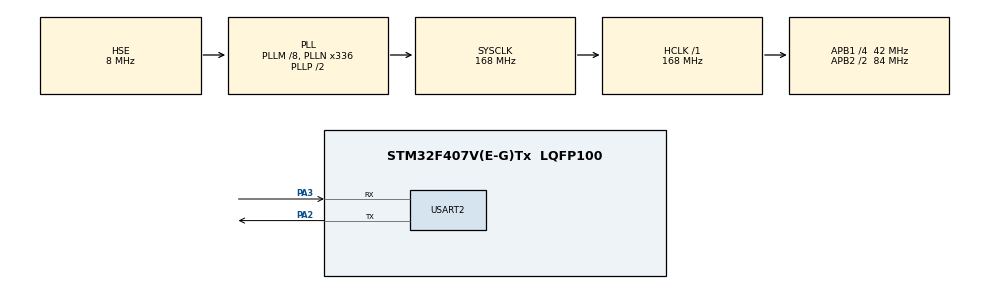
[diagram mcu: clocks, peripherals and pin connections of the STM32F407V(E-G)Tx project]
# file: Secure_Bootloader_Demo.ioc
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MBEDTLS.MBEDTLS_ASN1_WRITE_C=0
MBEDTLS.MBEDTLS_CAMELLIA_C=0
MBEDTLS.MBEDTLS_CERTS_C=0
MBEDTLS.MBEDTLS_CHACHA20_C=0
MBEDTLS.MBEDTLS_CIPHER_C=0
MBEDTLS.MBEDTLS_ECDH_C=0
MBEDTLS.MBEDTLS_ECP_C=0
MBEDTLS.MBEDTLS_GCM_C=0
MBEDTLS.MBEDTLS_GENPRIME=1
MBEDTLS.MBEDTLS_HKDF_C=0
MBEDTLS.MBEDTLS_MPI_MAX_SIZE=256
MBEDTLS.MBEDTLS_PKCS1_V15=1
MBEDTLS.MBEDTLS_PKCS1_V21=1
MBEDTLS.MBEDTLS_PLATFORM_C=0
MBEDTLS.MBEDTLS_POLY1305_C=0
MBEDTLS.MBEDTLS_RSA_C=1
MBEDTLS.MBEDTLS_SHA512_C=0
MBEDTLS.MBEDTLS_X509_USE_C=0
Mcu.Family=STM32F4
Mcu.Name=STM32F407V(E-G)Tx
Mcu.Package=LQFP100
NVIC.PriorityGroup=NVIC_PRIORITYGROUP_0
PA13.Mode=Serial_Wire
PA13.Signal=SYS_JTMS-SWDIO
PA14.Mode=Serial_Wire
PA14.Signal=SYS_JTCK-SWCLK
PA2.Mode=Asynchronous
PA2.Signal=USART2_TX
PA3.Mode=Asynchronous
PA3.Signal=USART2_RX
PH0-OSC_IN.Mode=HSE-External-Oscillator
PH0-OSC_IN.Signal=RCC_OSC_IN
PH1-OSC_OUT.Mode=HSE-External-Oscillator
PH1-OSC_OUT.Signal=RCC_OSC_OUT
ProjectManager.HeapSize=0x200
ProjectManager.StackSize=0x400
ProjectManager.TargetToolchain=STM32CubeIDE
RCC.48MHZClocksFreq_Value=48000000
RCC.AHBFreq_Value=168000000
RCC.APB1CLKDivider=RCC_HCLK_DIV4
RCC.APB1Freq_Value=42000000
RCC.APB1TimFreq_Value=84000000
RCC.APB2CLKDivider=RCC_HCLK_DIV2
RCC.APB2Freq_Value=84000000
RCC.APB2TimFreq_Value=168000000
RCC.CortexFreq_Value=168000000
RCC.HCLKFreq_Value=168000000
RCC.HSE_VALUE=8000000
RCC.HSI_VALUE=16000000
RCC.PLLM=8
RCC.PLLN=336
RCC.PLLQ=7
RCC.PLLSourceVirtual=RCC_PLLSOURCE_HSE
RCC.SYSCLKFreq_VALUE=168000000
RCC.SYSCLKSource=RCC_SYSCLKSOURCE_PLLCLK
RCC.VCOOutputFreq_Value=336000000
USART2.VirtualMode=VM_ASYNC
VP_MBEDTLS_VS_MBEDTLS.Mode=Enabled
VP_RNG_VS_RNG.Mode=RNG_Activate
board=STM32F407G-DISC1

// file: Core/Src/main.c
/* USER CODE BEGIN Header */
/**
  ******************************************************************************
  * @file           : main.c
  * @brief          : Main program body
  ******************************************************************************
  * @attention
  *
  * Copyright (c) 2026 STMicroelectronics.
  * All rights reserved.
  *
  * This software is licensed under terms that can be found in the LICENSE file
  * in the root directory of this software component.
  * If no LICENSE file comes with this software, it is provided AS-IS.
  *
  ******************************************************************************
  */
/* USER CODE END Header */
#include "main.h"
#include "mbedtls.h"

/* USER CODE BEGIN Includes */

#include "mbedtls/pk.h"
#include "mbedtls/sha256.h"
#include <string.h>
#include <stdio.h>
#include "rsa_keys.h"   /* public key only */

/* USER CODE END Includes */

/* USER CODE BEGIN PD */

#define BOOTLOADER_START_ADDR   (0x08000000U)
#define BOOT_HEADER_ADDR        (0x08010000U)
#define APP_START_ADDR          (0x08020000U)
#define BOOT_MAGIC              (0xB007B007U)

/* USER CODE END PD */

RNG_HandleTypeDef hrng;

UART_HandleTypeDef huart2;

void SystemClock_Config(void);
static void MX_GPIO_Init(void);
static void MX_RNG_Init(void);
static void MX_USART2_UART_Init(void);
/* USER CODE BEGIN PFP */

static mbedtls_pk_context rsa_pub_ctx;

static void Bootloader_InitCrypto(void);
static int Boot_CalcAppHash(const uint8_t *data, uint32_t len, uint8_t outHash[32]);
static int Boot_VerifySignature(const uint8_t hash[32],
                                const uint8_t *sig,
                                uint32_t sigLen);
static void Boot_JumpToApplication(void);
static void UART_Print(char *msg);   /* your existing UART function */
static void print_hex(const char *label, const uint8_t *buf, uint32_t len);

/* USER CODE END PFP */

/* USER CODE BEGIN 0 */

static void Bootloader_InitCrypto(void)
{
    mbedtls_pk_init(&rsa_pub_ctx);

    if (mbedtls_pk_parse_public_key(
            &rsa_pub_ctx,
            (const unsigned char *)rsa_public_key_pem,
            strlen(rsa_public_key_pem) + 1) != 0)
    {
        UART_Print("Public key parse failed\r\n");
        Error_Handler();
    }

    UART_Print("Public key parsed\r\n");
}

static int Boot_CalcAppHash(const uint8_t *data, uint32_t len, uint8_t outHash[32])
{
    if (mbedtls_sha256_ret(data, len, outHash, 0) != 0)
    {
        return -1;
    }

    return 0;
}

static int Boot_VerifySignature(const uint8_t hash[32],
                                const uint8_t *sig,
                                uint32_t sigLen)
{
    if (mbedtls_pk_verify(&rsa_pub_ctx,
                          MBEDTLS_MD_SHA256,
                          hash,
                          0,
                          sig,
                          sigLen) != 0)
    {
        return -1;
    }

    return 0;
}

static void Boot_JumpToApplication(void)
{
    uint32_t appStack = *(__IO uint32_t *)APP_START_ADDR;
    uint32_t appReset = *(__IO uint32_t *)(APP_START_ADDR + 4U);
    pFunction appEntry = (pFunction)appReset;

    UART_Print("Jumping to application\r\n");

    __disable_irq();

    /* stop SysTick */
    SysTick->CTRL = 0U;
    SysTick->LOAD = 0U;
    SysTick->VAL  = 0U;

    /* deinit HAL and clocks */
    HAL_RCC_DeInit();
    HAL_DeInit();

    /* disable all interrupts */
    for (uint32_t i = 0U; i < 8U; i++)
    {
        NVIC->ICER[i] = 0xFFFFFFFFU;
        NVIC->ICPR[i] = 0xFFFFFFFFU;
    }

    /* relocate vector table */
    SCB->VTOR = APP_START_ADDR;

    /* set application stack pointer */
    __set_MSP(appStack);

    appEntry();
}

static void UART_Print(char *msg)
{
    HAL_UART_Transmit(&huart2, (uint8_t *)msg, strlen(msg), HAL_MAX_DELAY);
}

static void print_hex(const char *label, const uint8_t *buf, uint32_t len)
{
    char tmp[8];

    UART_Print((char *)label);
    UART_Print(": ");

    for (uint32_t i = 0; i < len; i++)
    {
        sprintf(tmp, "%02X", buf[i]);
        UART_Print(tmp);
    }

    UART_Print("\r\n");
}

/* USER CODE END 0 */

int main(void)
{

  /* USER CODE BEGIN 1 */

  const Boot_ImageHeaderType *hdr;
  uint8_t calcHash[32];
  char tmp[32];

  /* USER CODE END 1 */

  /* MCU Configuration--------------------------------------------------------*/

  /* Reset of all peripherals, Initializes the Flash interface and the Systick. */
  HAL_Init();

  /* Configure the system clock */
  SystemClock_Config();

  /* Initialize all configured peripherals */
  MX_GPIO_Init();
  MX_RNG_Init();
  MX_USART2_UART_Init();
  MX_MBEDTLS_Init();
  /* USER CODE BEGIN 2 */

  UART_Print("\r\n=== BOOTLOADER START ===\r\n");

  Bootloader_InitCrypto();

  hdr = (const Boot_ImageHeaderType *)BOOT_HEADER_ADDR;

  if (hdr->magic != BOOT_MAGIC)
  {
      UART_Print("Header magic invalid\r\n");
      while (1)
      {
          UART_Print("Stay in bootloader\r\n");
          HAL_Delay(1000);
      }
  }

  UART_Print("Header OK\r\n");
  UART_Print("App size: ");
  sprintf(tmp, "%lu\r\n", (unsigned long)hdr->imageSize);
  UART_Print(tmp);

  /* hash the application image */
  if (Boot_CalcAppHash((const uint8_t *)APP_START_ADDR,
                       hdr->imageSize,
                       calcHash) != 0)
  {
      UART_Print("Hash failed\r\n");
      while (1)
      {
      }
  }

  UART_Print("App hash: ");
  print_hex("", calcHash, sizeof(calcHash));

  /* optional debug check: compare stored hash with computed hash */
  if (memcmp(calcHash, hdr->imageHash, 32) != 0)
  {
      UART_Print("Stored hash mismatch\r\n");
      while (1)
      {
          UART_Print("Stay in bootloader\r\n");
          HAL_Delay(1000);
      }
  }

  UART_Print("Hash match\r\n");

  /* verify RSA signature over the hash */
  if (Boot_VerifySignature(calcHash, hdr->signature, sizeof(hdr->signature)) != 0)
  {
      UART_Print("Signature verify failed\r\n");
      while (1)
      {
          UART_Print("Stay in bootloader\r\n");
          HAL_Delay(1000);
      }
  }

  UART_Print("Signature verify OK\r\n");

  Boot_JumpToApplication();

  /* USER CODE END 2 */

  /* Infinite loop */
  while (1)
  {

  }
}

void SystemClock_Config(void)
{
  RCC_OscInitTypeDef RCC_OscInitStruct = {0};
  RCC_ClkInitTypeDef RCC_ClkInitStruct = {0};

  /** Configure the main internal regulator output voltage
  */
  __HAL_RCC_PWR_CLK_ENABLE();
  __HAL_PWR_VOLTAGESCALING_CONFIG(PWR_REGULATOR_VOLTAGE_SCALE1);

  /** Initializes the RCC Oscillators according to the specified parameters
  * in the RCC_OscInitTypeDef structure.
  */
  RCC_OscInitStruct.OscillatorType = RCC_OSCILLATORTYPE_HSE;
  RCC_OscInitStruct.HSEState = RCC_HSE_ON;
  RCC_OscInitStruct.PLL.PLLState = RCC_PLL_ON;
  RCC_OscInitStruct.PLL.PLLSource = RCC_PLLSOURCE_HSE;
  RCC_OscInitStruct.PLL.PLLM = 8;
  RCC_OscInitStruct.PLL.PLLN = 336;
  RCC_OscInitStruct.PLL.PLLP = RCC_PLLP_DIV2;
  RCC_OscInitStruct.PLL.PLLQ = 7;
  if (HAL_RCC_OscConfig(&RCC_OscInitStruct) != HAL_OK)
  {
    Error_Handler();
  }

  /** Initializes the CPU, AHB and APB buses clocks
  */
  RCC_ClkInitStruct.ClockType = RCC_CLOCKTYPE_HCLK|RCC_CLOCKTYPE_SYSCLK
                              |RCC_CLOCKTYPE_PCLK1|RCC_CLOCKTYPE_PCLK2;
  RCC_ClkInitStruct.SYSCLKSource = RCC_SYSCLKSOURCE_PLLCLK;
  RCC_ClkInitStruct.AHBCLKDivider = RCC_SYSCLK_DIV1;
  RCC_ClkInitStruct.APB1CLKDivider = RCC_HCLK_DIV4;
  RCC_ClkInitStruct.APB2CLKDivider = RCC_HCLK_DIV2;

  if (HAL_RCC_ClockConfig(&RCC_ClkInitStruct, FLASH_LATENCY_5) != HAL_OK)
  {
    Error_Handler();
  }
}

static void MX_RNG_Init(void)
{

  hrng.Instance = RNG;
  if (HAL_RNG_Init(&hrng) != HAL_OK)
  {
    Error_Handler();
  }

}

static void MX_USART2_UART_Init(void)
{

  huart2.Instance = USART2;
  huart2.Init.BaudRate = 115200;
  huart2.Init.WordLength = UART_WORDLENGTH_8B;
  huart2.Init.StopBits = UART_STOPBITS_1;
  huart2.Init.Parity = UART_PARITY_NONE;
  huart2.Init.Mode = UART_MODE_TX_RX;
  huart2.Init.HwFlowCtl = UART_HWCONTROL_NONE;
  huart2.Init.OverSampling = UART_OVERSAMPLING_16;
  if (HAL_UART_Init(&huart2) != HAL_OK)
  {
    Error_Handler();
  }

}

static void MX_GPIO_Init(void)
{

  /* GPIO Ports Clock Enable */
  __HAL_RCC_GPIOH_CLK_ENABLE();
  __HAL_RCC_GPIOA_CLK_ENABLE();

}

void Error_Handler(void)
{
  __disable_irq();
  while (1)
  {
  }
}
